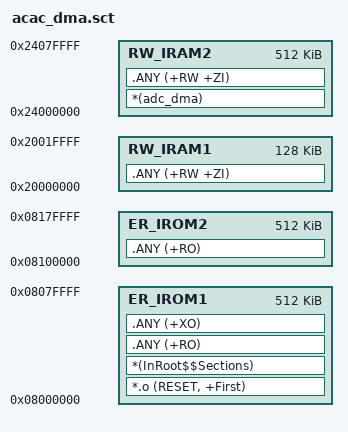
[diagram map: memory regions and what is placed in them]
; AC-AC scatter file selected by AC-AC.uvprojx.
; *************************************************************
; *** Scatter-Loading Description File generated by uVision ***
; *************************************************************

LR_IROM1 0x08000000 0x00080000  {    ; load region size_region
  ER_IROM1 0x08000000 0x00080000  {  ; load address = execution address
   *.o (RESET, +First)
   *(InRoot$$Sections)
   .ANY (+RO)
   .ANY (+XO)
  }
  RW_IRAM1 0x20000000 0x00020000  {  ; RW data
   .ANY (+RW +ZI)
  }
  RW_IRAM2 0x24000000 0x00080000  {
   ; DMA1 accesses AXI SRAM here. adc_sample.c places both buffers in adc_dma.
   *(adc_dma)
   .ANY (+RW +ZI)
  }
}

LR_IROM2 0x08100000 0x00080000  {
  ER_IROM2 0x08100000 0x00080000  {  ; load address = execution address
   .ANY (+RO)
  }
}
